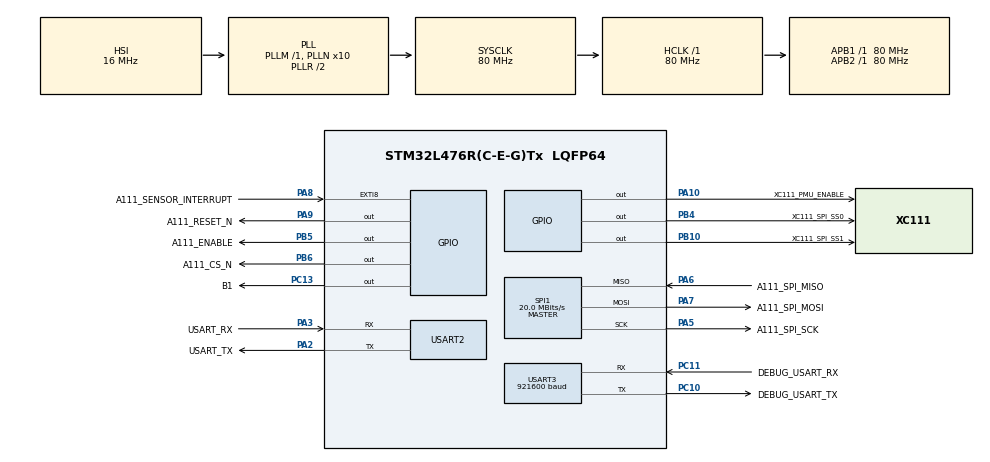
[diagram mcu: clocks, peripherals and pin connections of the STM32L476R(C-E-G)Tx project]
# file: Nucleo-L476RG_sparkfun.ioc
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Dma.Request0=USART2_RX
Dma.Request1=USART2_TX
Dma.Request2=SPI1_RX
Dma.Request3=SPI1_TX
Dma.SPI1_RX.2.Direction=DMA_PERIPH_TO_MEMORY
Dma.SPI1_RX.2.Instance=DMA1_Channel2
Dma.SPI1_RX.2.MemDataAlignment=DMA_MDATAALIGN_BYTE
Dma.SPI1_RX.2.MemInc=DMA_MINC_ENABLE
Dma.SPI1_RX.2.Mode=DMA_NORMAL
Dma.SPI1_RX.2.PeriphDataAlignment=DMA_PDATAALIGN_BYTE
Dma.SPI1_RX.2.PeriphInc=DMA_PINC_DISABLE
Dma.SPI1_RX.2.Priority=DMA_PRIORITY_LOW
Dma.SPI1_TX.3.Direction=DMA_MEMORY_TO_PERIPH
Dma.SPI1_TX.3.Instance=DMA1_Channel3
Dma.SPI1_TX.3.MemDataAlignment=DMA_MDATAALIGN_BYTE
Dma.SPI1_TX.3.MemInc=DMA_MINC_ENABLE
Dma.SPI1_TX.3.Mode=DMA_NORMAL
Dma.SPI1_TX.3.PeriphDataAlignment=DMA_PDATAALIGN_BYTE
Dma.SPI1_TX.3.PeriphInc=DMA_PINC_DISABLE
Dma.SPI1_TX.3.Priority=DMA_PRIORITY_LOW
Dma.USART2_RX.0.Direction=DMA_PERIPH_TO_MEMORY
Dma.USART2_RX.0.Instance=DMA1_Channel6
Dma.USART2_RX.0.MemDataAlignment=DMA_MDATAALIGN_BYTE
Dma.USART2_RX.0.MemInc=DMA_MINC_ENABLE
Dma.USART2_RX.0.Mode=DMA_NORMAL
Dma.USART2_RX.0.PeriphDataAlignment=DMA_PDATAALIGN_BYTE
Dma.USART2_RX.0.PeriphInc=DMA_PINC_DISABLE
Dma.USART2_RX.0.Priority=DMA_PRIORITY_LOW
Dma.USART2_TX.1.Direction=DMA_MEMORY_TO_PERIPH
Dma.USART2_TX.1.Instance=DMA1_Channel7
Dma.USART2_TX.1.MemDataAlignment=DMA_MDATAALIGN_BYTE
Dma.USART2_TX.1.MemInc=DMA_MINC_ENABLE
Dma.USART2_TX.1.Mode=DMA_NORMAL
Dma.USART2_TX.1.PeriphDataAlignment=DMA_PDATAALIGN_BYTE
Dma.USART2_TX.1.PeriphInc=DMA_PINC_DISABLE
Dma.USART2_TX.1.Priority=DMA_PRIORITY_LOW
Mcu.Family=STM32L4
Mcu.Name=STM32L476R(C-E-G)Tx
Mcu.Package=LQFP64
NVIC.DMA1_Channel2_IRQn=true\:0\:0\:false\:false\:true\:false\:true
NVIC.DMA1_Channel3_IRQn=true\:0\:0\:false\:false\:true\:false\:true
NVIC.DMA1_Channel6_IRQn=true\:0\:0\:false\:false\:true\:false\:true
NVIC.DMA1_Channel7_IRQn=true\:0\:0\:false\:false\:true\:false\:true
NVIC.EXTI9_5_IRQn=true\:0\:0\:false\:false\:true\:true\:true
NVIC.PriorityGroup=NVIC_PRIORITYGROUP_4
NVIC.SPI1_IRQn=true\:0\:0\:false\:false\:true\:true\:true
NVIC.USART2_IRQn=true\:0\:0\:false\:false\:true\:true\:true
PA10.GPIO_Label=XC111_PMU_ENABLE
PA10.Signal=GPIO_Output
PA13\ (JTMS-SWDIO).Mode=Serial_Wire
PA13\ (JTMS-SWDIO).Signal=SYS_JTMS-SWDIO
PA14\ (JTCK-SWCLK).Mode=Serial_Wire
PA14\ (JTCK-SWCLK).Signal=SYS_JTCK-SWCLK
PA2.GPIO_Label=USART_TX
PA2.Mode=Asynchronous
PA2.Signal=USART2_TX
PA3.GPIO_Label=USART_RX
PA3.Mode=Asynchronous
PA3.Signal=USART2_RX
PA5.GPIO_Label=A111_SPI_SCK
PA5.Mode=Full_Duplex_Master
PA5.Signal=SPI1_SCK
PA6.GPIO_Label=A111_SPI_MISO
PA6.Mode=Full_Duplex_Master
PA6.Signal=SPI1_MISO
PA7.GPIO_Label=A111_SPI_MOSI
PA7.Mode=Full_Duplex_Master
PA7.Signal=SPI1_MOSI
PA8.GPIO_Label=A111_SENSOR_INTERRUPT
PA8.GPIO_ModeDefaultEXTI=GPIO_MODE_IT_RISING
PA8.Signal=GPXTI8
PA9.GPIO_Label=A111_RESET_N
PA9.Signal=GPIO_Output
PB10.GPIO_Label=XC111_SPI_SS1
PB10.Signal=GPIO_Output
PB4\ (NJTRST).GPIO_Label=XC111_SPI_SS0
PB4\ (NJTRST).Signal=GPIO_Output
PB5.GPIO_Label=A111_ENABLE
PB5.Signal=GPIO_Output
PB6.GPIO_Label=A111_CS_N
PB6.Signal=GPIO_Output
PC10.GPIO_Label=DEBUG_USART_TX
PC10.Mode=Asynchronous
PC10.Signal=USART3_TX
PC11.GPIO_Label=DEBUG_USART_RX
PC11.Mode=Asynchronous
PC11.Signal=USART3_RX
PC13.GPIO_Label=B1
PC13.Signal=GPIO_Output
ProjectManager.HeapSize=0x200
ProjectManager.StackSize=0x2000
ProjectManager.TargetToolchain=Makefile
RCC.ADCFreq_Value=64000000
RCC.AHBFreq_Value=80000000
RCC.APB1Freq_Value=80000000
RCC.APB1TimFreq_Value=80000000
RCC.APB2Freq_Value=80000000
RCC.APB2TimFreq_Value=80000000
RCC.CortexFreq_Value=80000000
RCC.HCLKFreq_Value=80000000
RCC.HSE_VALUE=8000000
RCC.HSICalibrationValue=16
RCC.HSI_VALUE=16000000
RCC.LSE_VALUE=32768
RCC.MSI_VALUE=4000000
RCC.PLLN=10
RCC.PLLSourceVirtual=RCC_PLLSOURCE_HSI
RCC.PREFETCH_ENABLE=1
RCC.SYSCLKFreq_VALUE=80000000
RCC.SYSCLKSource=RCC_SYSCLKSOURCE_PLLCLK
RCC.USBFreq_Value=64000000
RCC.VCOOutputFreq_Value=160000000
SPI1.BaudRatePrescaler=SPI_BAUDRATEPRESCALER_4
SPI1.CalculateBaudRate=20.0 MBits/s
SPI1.DataSize=SPI_DATASIZE_8BIT
SPI1.Direction=SPI_DIRECTION_2LINES
SPI1.Mode=SPI_MODE_MASTER
SPI1.VirtualType=VM_MASTER
USART2.VirtualMode-Asynchronous=VM_ASYNC
USART3.BaudRate=921600
USART3.VirtualMode-Asynchronous=VM_ASYNC
board=custom

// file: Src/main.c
/* USER CODE BEGIN Header */
/**
  ******************************************************************************
  * @file           : main.c
  * @brief          : Main program body
  ******************************************************************************
  * @attention
  *
  * <h2><center>&copy; Copyright (c) 2020 STMicroelectronics.
  * All rights reserved.</center></h2>
  *
  * This software component is licensed by ST under BSD 3-Clause license,
  * the "License"; You may not use this file except in compliance with the
  * License. You may obtain a copy of the License at:
  *                        opensource.org/licenses/BSD-3-Clause
  *
  ******************************************************************************
  */
/* USER CODE END Header */
#include "main.h"

/* USER CODE BEGIN Includes */
#include <stdio.h>

#include "acc_module_server.h"
/* USER CODE END Includes */

SPI_HandleTypeDef hspi1;
DMA_HandleTypeDef hdma_spi1_rx;
DMA_HandleTypeDef hdma_spi1_tx;

UART_HandleTypeDef huart2;
UART_HandleTypeDef huart3;
DMA_HandleTypeDef hdma_usart2_rx;
DMA_HandleTypeDef hdma_usart2_tx;

void SystemClock_Config(void);
static void MX_GPIO_Init(void);
static void MX_DMA_Init(void);
static void MX_SPI1_Init(void);
static void MX_USART2_UART_Init(void);
static void MX_USART3_UART_Init(void);

int main(void)
{

  /* MCU Configuration--------------------------------------------------------*/

  /* Reset of all peripherals, Initializes the Flash interface and the Systick. */
  HAL_Init();

  /* Configure the system clock */
  SystemClock_Config();

  /* Initialize all configured peripherals */
  MX_GPIO_Init();
  MX_DMA_Init();
  MX_SPI1_Init();
  MX_USART2_UART_Init();
  MX_USART3_UART_Init();
  /* USER CODE BEGIN 2 */

  acc_ms_enable_distance();
  acc_ms_enable_envelope();
  acc_ms_enable_iq();
  acc_ms_enable_obstacle();
  acc_ms_enable_power_bin();
  acc_ms_enable_presence();
  acc_ms_enable_sparse();

  ms_main(0xEB00);

  /* USER CODE END 2 */

  /* Infinite loop */
  while (1)
  {

  }
}

void SystemClock_Config(void)
{
  RCC_OscInitTypeDef RCC_OscInitStruct = {0};
  RCC_ClkInitTypeDef RCC_ClkInitStruct = {0};

  /** Configure the main internal regulator output voltage
  */
  if (HAL_PWREx_ControlVoltageScaling(PWR_REGULATOR_VOLTAGE_SCALE1) != HAL_OK)
  {
    Error_Handler();
  }
  /** Initializes the RCC Oscillators according to the specified parameters
  * in the RCC_OscInitTypeDef structure.
  */
  RCC_OscInitStruct.OscillatorType = RCC_OSCILLATORTYPE_HSI;
  RCC_OscInitStruct.HSIState = RCC_HSI_ON;
  RCC_OscInitStruct.HSICalibrationValue = RCC_HSICALIBRATION_DEFAULT;
  RCC_OscInitStruct.PLL.PLLState = RCC_PLL_ON;
  RCC_OscInitStruct.PLL.PLLSource = RCC_PLLSOURCE_HSI;
  RCC_OscInitStruct.PLL.PLLM = 1;
  RCC_OscInitStruct.PLL.PLLN = 10;
  RCC_OscInitStruct.PLL.PLLP = RCC_PLLP_DIV7;
  RCC_OscInitStruct.PLL.PLLQ = RCC_PLLQ_DIV2;
  RCC_OscInitStruct.PLL.PLLR = RCC_PLLR_DIV2;
  if (HAL_RCC_OscConfig(&RCC_OscInitStruct) != HAL_OK)
  {
    Error_Handler();
  }
  /** Initializes the CPU, AHB and APB buses clocks
  */
  RCC_ClkInitStruct.ClockType = RCC_CLOCKTYPE_HCLK|RCC_CLOCKTYPE_SYSCLK
                              |RCC_CLOCKTYPE_PCLK1|RCC_CLOCKTYPE_PCLK2;
  RCC_ClkInitStruct.SYSCLKSource = RCC_SYSCLKSOURCE_PLLCLK;
  RCC_ClkInitStruct.AHBCLKDivider = RCC_SYSCLK_DIV1;
  RCC_ClkInitStruct.APB1CLKDivider = RCC_HCLK_DIV1;
  RCC_ClkInitStruct.APB2CLKDivider = RCC_HCLK_DIV1;

  if (HAL_RCC_ClockConfig(&RCC_ClkInitStruct, FLASH_LATENCY_4) != HAL_OK)
  {
    Error_Handler();
  }
}

static void MX_SPI1_Init(void)
{

  /* SPI1 parameter configuration*/
  hspi1.Instance = SPI1;
  hspi1.Init.Mode = SPI_MODE_MASTER;
  hspi1.Init.Direction = SPI_DIRECTION_2LINES;
  hspi1.Init.DataSize = SPI_DATASIZE_8BIT;
  hspi1.Init.CLKPolarity = SPI_POLARITY_LOW;
  hspi1.Init.CLKPhase = SPI_PHASE_1EDGE;
  hspi1.Init.NSS = SPI_NSS_SOFT;
  hspi1.Init.BaudRatePrescaler = SPI_BAUDRATEPRESCALER_4;
  hspi1.Init.FirstBit = SPI_FIRSTBIT_MSB;
  hspi1.Init.TIMode = SPI_TIMODE_DISABLE;
  hspi1.Init.CRCCalculation = SPI_CRCCALCULATION_DISABLE;
  hspi1.Init.CRCPolynomial = 7;
  hspi1.Init.CRCLength = SPI_CRC_LENGTH_DATASIZE;
  hspi1.Init.NSSPMode = SPI_NSS_PULSE_ENABLE;
  if (HAL_SPI_Init(&hspi1) != HAL_OK)
  {
    Error_Handler();
  }

}

static void MX_USART2_UART_Init(void)
{

  huart2.Instance = USART2;
  huart2.Init.BaudRate = 115200;
  huart2.Init.WordLength = UART_WORDLENGTH_8B;
  huart2.Init.StopBits = UART_STOPBITS_1;
  huart2.Init.Parity = UART_PARITY_NONE;
  huart2.Init.Mode = UART_MODE_TX_RX;
  huart2.Init.HwFlowCtl = UART_HWCONTROL_NONE;
  huart2.Init.OverSampling = UART_OVERSAMPLING_16;
  huart2.Init.OneBitSampling = UART_ONE_BIT_SAMPLE_DISABLE;
  huart2.AdvancedInit.AdvFeatureInit = UART_ADVFEATURE_NO_INIT;
  if (HAL_UART_Init(&huart2) != HAL_OK)
  {
    Error_Handler();
  }
  /* USER CODE BEGIN USART2_Init 2 */

  /**
   * Set receiver timeout to 100 bits.
   * Receiver timeout is used to be able to receive packages of
   * different length with the UART DMA RX function.
   */
  HAL_UART_ReceiverTimeout_Config(&huart2, 100);

  /* USER CODE END USART2_Init 2 */

}

static void MX_USART3_UART_Init(void)
{

  huart3.Instance = USART3;
  huart3.Init.BaudRate = 921600;
  huart3.Init.WordLength = UART_WORDLENGTH_8B;
  huart3.Init.StopBits = UART_STOPBITS_1;
  huart3.Init.Parity = UART_PARITY_NONE;
  huart3.Init.Mode = UART_MODE_TX_RX;
  huart3.Init.HwFlowCtl = UART_HWCONTROL_NONE;
  huart3.Init.OverSampling = UART_OVERSAMPLING_16;
  huart3.Init.OneBitSampling = UART_ONE_BIT_SAMPLE_DISABLE;
  huart3.AdvancedInit.AdvFeatureInit = UART_ADVFEATURE_NO_INIT;
  if (HAL_UART_Init(&huart3) != HAL_OK)
  {
    Error_Handler();
  }

}

static void MX_DMA_Init(void)
{

  /* DMA controller clock enable */
  __HAL_RCC_DMA1_CLK_ENABLE();

  /* DMA interrupt init */
  /* DMA1_Channel2_IRQn interrupt configuration */
  HAL_NVIC_SetPriority(DMA1_Channel2_IRQn, 0, 0);
  HAL_NVIC_EnableIRQ(DMA1_Channel2_IRQn);
  /* DMA1_Channel3_IRQn interrupt configuration */
  HAL_NVIC_SetPriority(DMA1_Channel3_IRQn, 0, 0);
  HAL_NVIC_EnableIRQ(DMA1_Channel3_IRQn);
  /* DMA1_Channel6_IRQn interrupt configuration */
  HAL_NVIC_SetPriority(DMA1_Channel6_IRQn, 0, 0);
  HAL_NVIC_EnableIRQ(DMA1_Channel6_IRQn);
  /* DMA1_Channel7_IRQn interrupt configuration */
  HAL_NVIC_SetPriority(DMA1_Channel7_IRQn, 0, 0);
  HAL_NVIC_EnableIRQ(DMA1_Channel7_IRQn);

}

static void MX_GPIO_Init(void)
{
  GPIO_InitTypeDef GPIO_InitStruct = {0};

  /* GPIO Ports Clock Enable */
  __HAL_RCC_GPIOC_CLK_ENABLE();
  __HAL_RCC_GPIOA_CLK_ENABLE();
  __HAL_RCC_GPIOB_CLK_ENABLE();

  /*Configure GPIO pin Output Level */
  HAL_GPIO_WritePin(GPIOC, B1_Pin, GPIO_PIN_RESET);

  /*Configure GPIO pin Output Level */
  HAL_GPIO_WritePin(GPIOB, XC111_SPI_SS1_Pin|XC111_SPI_SS0_Pin|A111_ENABLE_Pin|A111_CS_N_Pin, GPIO_PIN_RESET);

  /*Configure GPIO pin Output Level */
  HAL_GPIO_WritePin(GPIOA, A111_RESET_N_Pin|XC111_PMU_ENABLE_Pin, GPIO_PIN_RESET);

  /*Configure GPIO pins : B1_Pin */
  GPIO_InitStruct.Pin = B1_Pin;
  GPIO_InitStruct.Mode = GPIO_MODE_OUTPUT_PP;
  GPIO_InitStruct.Pull = GPIO_NOPULL;
  GPIO_InitStruct.Speed = GPIO_SPEED_FREQ_LOW;
  HAL_GPIO_Init(GPIOC, &GPIO_InitStruct);

  /*Configure GPIO pins : XC111_SPI_SS1_Pin XC111_SPI_SS0_Pin A111_ENABLE_Pin A111_CS_N_Pin */
  GPIO_InitStruct.Pin = XC111_SPI_SS1_Pin|XC111_SPI_SS0_Pin|A111_ENABLE_Pin|A111_CS_N_Pin;
  GPIO_InitStruct.Mode = GPIO_MODE_OUTPUT_PP;
  GPIO_InitStruct.Pull = GPIO_NOPULL;
  GPIO_InitStruct.Speed = GPIO_SPEED_FREQ_LOW;
  HAL_GPIO_Init(GPIOB, &GPIO_InitStruct);

  /*Configure GPIO pin : A111_SENSOR_INTERRUPT_Pin */
  GPIO_InitStruct.Pin = A111_SENSOR_INTERRUPT_Pin;
  GPIO_InitStruct.Mode = GPIO_MODE_IT_RISING;
  GPIO_InitStruct.Pull = GPIO_NOPULL;
  HAL_GPIO_Init(A111_SENSOR_INTERRUPT_GPIO_Port, &GPIO_InitStruct);

  /*Configure GPIO pins : A111_RESET_N_Pin XC111_PMU_ENABLE_Pin */
  GPIO_InitStruct.Pin = A111_RESET_N_Pin|XC111_PMU_ENABLE_Pin;
  GPIO_InitStruct.Mode = GPIO_MODE_OUTPUT_PP;
  GPIO_InitStruct.Pull = GPIO_NOPULL;
  GPIO_InitStruct.Speed = GPIO_SPEED_FREQ_LOW;
  HAL_GPIO_Init(GPIOA, &GPIO_InitStruct);

  /* EXTI interrupt init*/
  HAL_NVIC_SetPriority(EXTI9_5_IRQn, 0, 0);
  HAL_NVIC_EnableIRQ(EXTI9_5_IRQn);

}

void Error_Handler(void)
{
}

/************************ (C) COPYRIGHT STMicroelectronics *****END OF FILE****/
